# ATSAM3X8C register map
Vendor: Atmel; File version: 0
CPU: CM3 r2p0, selectable endian, no MPU, no FPU, 0x4 interrupt priority bits, 0x0 interrupts
Registers are 32-bit, read-write, no defined reset value unless marked. A register's access mark holds for its fields unless they carry their own. Offsets are from the block's base; [hi:lo] are bit positions; {n}, {i} and the like mark numbered series; 'fields as' and 'values as' point back to an identical list.

## DMAC — DMA Controller
Base 0x400C4000; register names take the prefix DMAC_
0x00 GCFG reset 0x10 — DMAC Global Configuration Register
  [4] ARB_CFG — Arbiter Configuration
    0=FIXED (Fixed priority arbiter (see "Basic Definitions" )); 1=ROUND_ROBIN (Modified round robin arbiter.)
0x04 EN reset 0x0 — DMAC Enable Register
  [0] ENABLE — General Enable of DMA
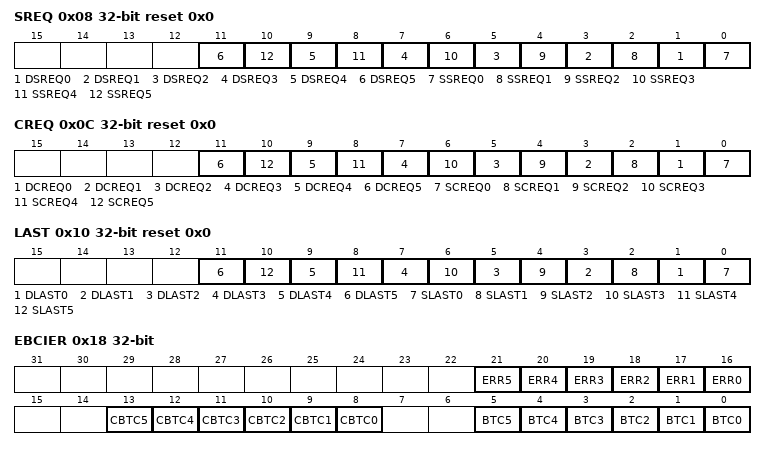
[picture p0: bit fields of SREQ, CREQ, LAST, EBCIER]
0x08 SREQ reset 0x0 — DMAC Software Single Request Register
  [2n+1] DSREQ{n} (n=0..5) — Destination Request
  [2n] SSREQ{n} (n=0..5) — Source Request
0x0C CREQ reset 0x0 — DMAC Software Chunk Transfer Request Register
  [2n+1] DCREQ{n} (n=0..5) — Destination Chunk Request
  [2n] SCREQ{n} (n=0..5) — Source Chunk Request
0x10 LAST reset 0x0 — DMAC Software Last Transfer Flag Register
  [2n+1] DLAST{n} (n=0..5) — Destination Last
  [2n] SLAST{n} (n=0..5) — Source Last
0x18 EBCIER wo — DMAC Error, Chained Buffer Transfer Completed Interrupt and Buffer Transfer Completed Interrupt Enable register.
  [n+16] ERR{n} (n=0..5) — Access Error [5:0]
  [n+8] CBTC{n} (n=0..5) — Chained Buffer Transfer Completed [5:0]
  [n] BTC{n} (n=0..5) — Buffer Transfer Completed [5:0]
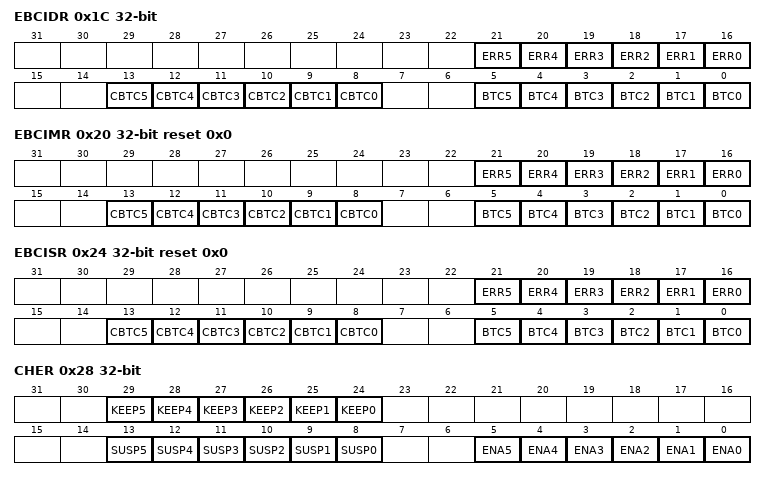
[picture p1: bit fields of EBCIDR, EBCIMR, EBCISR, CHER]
0x1C EBCIDR wo — DMAC Error, Chained Buffer Transfer Completed Interrupt and Buffer Transfer Completed Interrupt Disable register.
  fields as EBCIER
0x20 EBCIMR ro reset 0x0 — DMAC Error, Chained Buffer Transfer Completed Interrupt and Buffer transfer completed Mask Register.
  fields as EBCIER
0x24 EBCISR ro reset 0x0 — DMAC Error, Chained Buffer Transfer Completed Interrupt and Buffer transfer completed Status Register.
  fields as EBCIER
0x28 CHER wo — DMAC Channel Handler Enable Register
  [n+24] KEEP{n} (n=0..5) — Keep on [5:0]
  [n+8] SUSP{n} (n=0..5) — Suspend [5:0]
  [n] ENA{n} (n=0..5) — Enable [5:0]
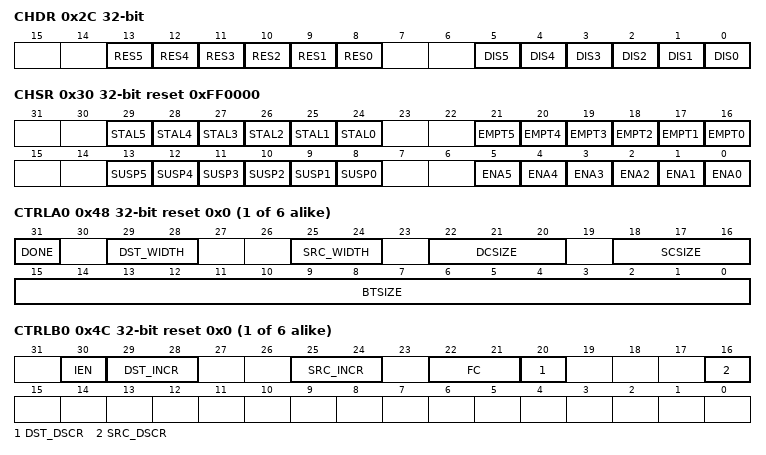
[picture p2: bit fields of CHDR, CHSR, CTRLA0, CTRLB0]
0x2C CHDR wo — DMAC Channel Handler Disable Register
  [n+8] RES{n} (n=0..5) — Resume [5:0]
  [n] DIS{n} (n=0..5) — Disable [5:0]
0x30 CHSR ro reset 0xFF0000 — DMAC Channel Handler Status Register
  [n+24] STAL{n} (n=0..5) — Stalled [5:0]
  [n+16] EMPT{n} (n=0..5) — Empty [5:0]
  [n+8] SUSP{n} (n=0..5) — Suspend [5:0]
  [n] ENA{n} (n=0..5) — Enable [5:0]
{0x3C+0x28*i} SADDR{i} reset 0x0 (i=0..5) — DMAC Channel Source Address Register (ch_num = {i})
  [31:0] SADDR — Channel x Source Address
{0x40+0x28*i} DADDR{i} reset 0x0 (i=0..5) — DMAC Channel Destination Address Register (ch_num = {i})
  [31:0] DADDR — Channel x Destination Address
{0x44+0x28*i} DSCR{i} reset 0x0 (i=0..5) — DMAC Channel Descriptor Address Register (ch_num = {i})
  [31:2] DSCR — Buffer Transfer Descriptor Address
{0x48+0x28*i} CTRLA{i} reset 0x0 (i=0..5) — DMAC Channel Control A Register (ch_num = {i})
  [31] DONE — Current Descriptor Stop Command and Transfer Completed Memory Indicator
  [29:28] DST_WIDTH — Transfer Width for the Destination
    0=BYTE (the transfer size is set to 8-bit width); 1=HALF_WORD (the transfer size is set to 16-bit width); 2=WORD (the transfer size is set to 32-bit width)
  [25:24] SRC_WIDTH — Transfer Width for the Source
    values as DST_WIDTH
  [22:20] DCSIZE — Destination Chunk Transfer Size
    0=CHK_1 (1 data transferred); 1=CHK_4 (4 data transferred); 2=CHK_8 (8 data transferred); 3=CHK_16 (16 data transferred)
  [18:16] SCSIZE — Source Chunk Transfer Size.
    values as DCSIZE
  [15:0] BTSIZE — Buffer Transfer Size
{0x4C+0x28*i} CTRLB{i} reset 0x0 (i=0..5) — DMAC Channel Control B Register (ch_num = {i})
  [30] IEN — Interrupt Enable Not
  [29:28] DST_INCR — Incrementing, Decrementing or Fixed Address for the Destination
    0=INCREMENTING (The destination address is incremented); 1=DECREMENTING (The destination address is decremented); 2=FIXED (The destination address remains unchanged)
  [25:24] SRC_INCR — Incrementing, Decrementing or Fixed Address for the Source
    0=INCREMENTING (The source address is incremented); 1=DECREMENTING (The source address is decremented); 2=FIXED (The source address remains unchanged)
  [22:21] FC — Flow Control
    0=MEM2MEM_DMA_FC (Memory-to-Memory Transfer DMAC is flow controller); 1=MEM2PER_DMA_FC (Memory-to-Peripheral Transfer DMAC is flow controller); 2=PER2MEM_DMA_FC (Peripheral-to-Memory Transfer DMAC is flow controller); 3=PER2PER_DMA_FC (Peripheral-to-Peripheral Transfer DMAC is flow controller)
  [20] DST_DSCR — Destination Address Descriptor
    0=FETCH_FROM_MEM (Destination address is updated when the descriptor is fetched from the memory.); 1=FETCH_DISABLE (Buffer Descriptor Fetch operation is disabled for the destination.)
  [16] SRC_DSCR — Source Address Descriptor
    0=FETCH_FROM_MEM (Source address is updated when the descriptor is fetched from the memory.); 1=FETCH_DISABLE (Buffer Descriptor Fetch operation is disabled for the source.)
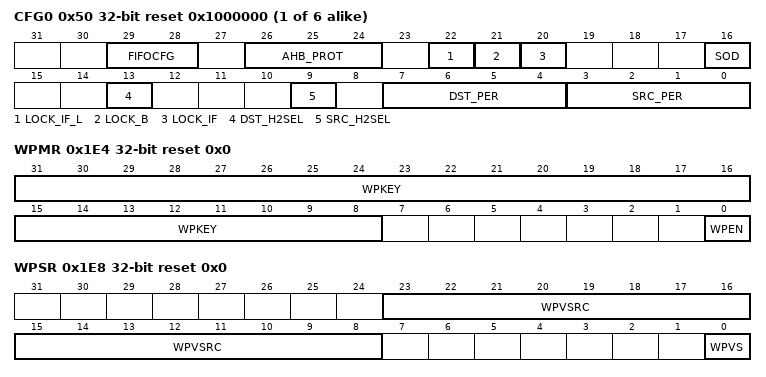
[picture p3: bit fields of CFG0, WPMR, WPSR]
{0x50+0x28*i} CFG{i} reset 0x1000000 (i=0..5) — DMAC Channel Configuration Register (ch_num = {i})
  [29:28] FIFOCFG — FIFO Configuration
    0=ALAP_CFG (The largest defined length AHB burst is performed on the destination AHB interface.); 1=HALF_CFG (When half FIFO size is available/filled, a source/destination request is serviced.); 2=ASAP_CFG (When there is enough space/data available to perform a single AHB access, then the request is serviced.)
  [26:24] AHB_PROT — AHB Protection
  [22] LOCK_IF_L — Master Interface Arbiter Lock
    0=CHUNK (The Master Interface Arbiter is locked by the channel x for a chunk transfer.); 1=BUFFER (The Master Interface Arbiter is locked by the channel x for a buffer transfer.)
  [21] LOCK_B — Bus Lock
    0=DISABLE (AHB Bus Locking capability is disabled.)
  [20] LOCK_IF — Interface Lock
    0=DISABLE (Interface Lock capability is disabled); 1=ENABLE (Interface Lock capability is enabled)
  [16] SOD — Stop On Done
    0=DISABLE (STOP ON DONE disabled, the descriptor fetch operation ignores DONE Field of CTRLA register.); 1=ENABLE (STOP ON DONE activated, the DMAC module is automatically disabled if DONE FIELD is set to 1.)
  [13] DST_H2SEL — Software or Hardware Selection for the Destination
    0=SW (Software handshaking interface is used to trigger a transfer request.); 1=HW (Hardware handshaking interface is used to trigger a transfer request.)
  [9] SRC_H2SEL — Software or Hardware Selection for the Source
    values as DST_H2SEL
  [7:4] DST_PER — Destination with Peripheral identifier
  [3:0] SRC_PER — Source with Peripheral identifier
0x1E4 WPMR reset 0x0 — DMAC Write Protect Mode Register
  [31:8] WPKEY — Write Protect KEY
    0x444D41=PASSWD (Writing any other value in this field aborts the write operation of the WPEN bit.Always reads as 0.)
  [0] WPEN — Write Protect Enable
0x1E8 WPSR ro reset 0x0 — DMAC Write Protect Status Register
  [23:8] WPVSRC — Write Protect Violation Source
  [0] WPVS — Write Protect Violation Status
